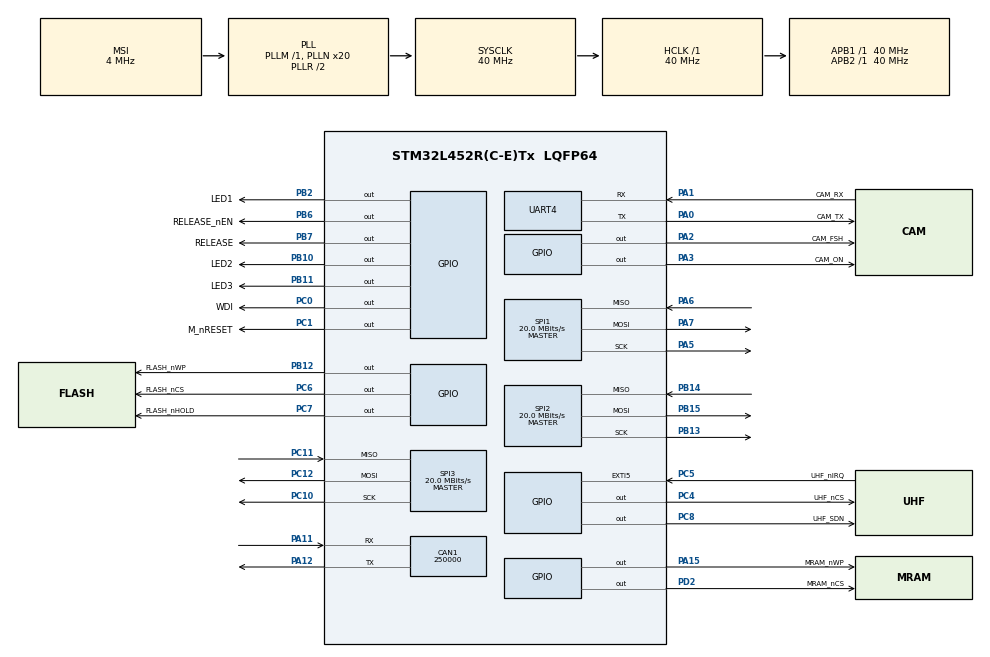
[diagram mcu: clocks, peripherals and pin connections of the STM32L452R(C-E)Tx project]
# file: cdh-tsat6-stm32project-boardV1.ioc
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CAN1.BS1=CAN_BS1_5TQ
CAN1.BS2=CAN_BS2_4TQ
CAN1.CalculateBaudRate=250000
CAN1.CalculateTimeBit=4000
CAN1.CalculateTimeQuantum=400.0
CAN1.Mode=CAN_MODE_LOOPBACK
Mcu.Family=STM32L4
Mcu.Name=STM32L452R(C-E)Tx
Mcu.Package=LQFP64
NVIC.CAN1_RX0_IRQn=true\:0\:0\:false\:false\:true\:true\:true\:true
NVIC.PriorityGroup=NVIC_PRIORITYGROUP_4
NVIC.TIM6_DAC_IRQn=true\:15\:0\:false\:false\:true\:false\:true\:true
NVIC.TimeBase=TIM6_DAC_IRQn
NVIC.TimeBaseIP=TIM6
PA0.GPIO_Label=CAM_TX
PA0.Mode=Asynchronous
PA0.Signal=UART4_TX
PA1.GPIO_Label=CAM_RX
PA1.Mode=Asynchronous
PA1.Signal=UART4_RX
PA11.Mode=CAN_Activate
PA11.Signal=CAN1_RX
PA12.Mode=CAN_Activate
PA12.Signal=CAN1_TX
PA13\ (JTMS/SWDIO).Mode=Trace_Asynchronous_SW
PA13\ (JTMS/SWDIO).Signal=SYS_JTMS-SWDIO
PA14\ (JTCK/SWCLK).Mode=Trace_Asynchronous_SW
PA14\ (JTCK/SWCLK).Signal=SYS_JTCK-SWCLK
PA15\ (JTDI).GPIO_Label=MRAM_nWP
PA15\ (JTDI).Signal=GPIO_Output
PA2.GPIO_Label=CAM_FSH
PA2.Signal=GPIO_Output
PA3.GPIO_Label=CAM_ON
PA3.Signal=GPIO_Output
PA5.Mode=Full_Duplex_Master
PA5.Signal=SPI1_SCK
PA6.Mode=Full_Duplex_Master
PA6.Signal=SPI1_MISO
PA7.Mode=Full_Duplex_Master
PA7.Signal=SPI1_MOSI
PB10.GPIO_Label=LED2
PB10.Signal=GPIO_Output
PB11.GPIO_Label=LED3
PB11.Signal=GPIO_Output
PB12.GPIO_Label=FLASH_nWP
PB12.Signal=GPIO_Output
PB13.Mode=Full_Duplex_Master
PB13.Signal=SPI2_SCK
PB14.Mode=Full_Duplex_Master
PB14.Signal=SPI2_MISO
PB15.Mode=Full_Duplex_Master
PB15.Signal=SPI2_MOSI
PB2.GPIO_Label=LED1
PB2.Signal=GPIO_Output
PB3\ (JTDO/TRACESWO).Mode=Trace_Asynchronous_SW
PB3\ (JTDO/TRACESWO).Signal=SYS_JTDO-SWO
PB6.GPIO_Label=RELEASE_nEN
PB6.Signal=GPIO_Output
PB7.GPIO_Label=RELEASE
PB7.Signal=GPIO_Output
PC0.GPIO_Label=WDI
PC0.Signal=GPIO_Output
PC1.GPIO_Label=M_nRESET
PC1.Signal=GPIO_Output
PC10.Mode=Full_Duplex_Master
PC10.Signal=SPI3_SCK
PC11.Mode=Full_Duplex_Master
PC11.Signal=SPI3_MISO
PC12.Mode=Full_Duplex_Master
PC12.Signal=SPI3_MOSI
PC4.GPIO_Label=UHF_nCS
PC4.Signal=GPIO_Output
PC5.GPIO_Label=UHF_nIRQ
PC5.Signal=GPXTI5
PC6.GPIO_Label=FLASH_nCS
PC6.Signal=GPIO_Output
PC7.GPIO_Label=FLASH_nHOLD
PC7.Signal=GPIO_Output
PC8.GPIO_Label=UHF_SDN
PC8.Signal=GPIO_Output
PD2.GPIO_Label=MRAM_nCS
PD2.Signal=GPIO_Output
ProjectManager.HeapSize=0x200
ProjectManager.StackSize=0x400
ProjectManager.TargetToolchain=STM32CubeIDE
RCC.ADCFreq_Value=16000000
RCC.AHBFreq_Value=40000000
RCC.APB1Freq_Value=40000000
RCC.APB1TimFreq_Value=40000000
RCC.APB2Freq_Value=40000000
RCC.APB2TimFreq_Value=40000000
RCC.CortexFreq_Value=40000000
RCC.HCLKFreq_Value=40000000
RCC.HSE_VALUE=8000000
RCC.HSI48_VALUE=48000000
RCC.HSI_VALUE=16000000
RCC.LSE_VALUE=32768
RCC.MSI_VALUE=4000000
RCC.PLLN=20
RCC.SYSCLKFreq_VALUE=40000000
RCC.SYSCLKSource=RCC_SYSCLKSOURCE_PLLCLK
RCC.USBFreq_Value=16000000
RCC.VCOOutputFreq_Value=80000000
SPI1.BaudRatePrescaler=SPI_BAUDRATEPRESCALER_2
SPI1.CalculateBaudRate=20.0 MBits/s
SPI1.DataSize=SPI_DATASIZE_8BIT
SPI1.Direction=SPI_DIRECTION_2LINES
SPI1.Mode=SPI_MODE_MASTER
SPI1.VirtualType=VM_MASTER
SPI2.BaudRatePrescaler=SPI_BAUDRATEPRESCALER_2
SPI2.CalculateBaudRate=20.0 MBits/s
SPI2.DataSize=SPI_DATASIZE_8BIT
SPI2.Direction=SPI_DIRECTION_2LINES
SPI2.Mode=SPI_MODE_MASTER
SPI2.VirtualType=VM_MASTER
SPI3.BaudRatePrescaler=SPI_BAUDRATEPRESCALER_2
SPI3.CalculateBaudRate=20.0 MBits/s
SPI3.DataSize=SPI_DATASIZE_8BIT
SPI3.Direction=SPI_DIRECTION_2LINES
SPI3.Mode=SPI_MODE_MASTER
SPI3.VirtualType=VM_MASTER
VP_RTC_VS_RTC_Activate.Mode=RTC_Enabled
VP_SYS_VS_tim6.Mode=TIM6
board=custom

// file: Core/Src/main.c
/* USER CODE BEGIN Header */
/**
  ******************************************************************************
  * @file           : main.c
  * @brief          : Main program body
  ******************************************************************************
  * @attention
  *
  * Copyright (c) 2022 STMicroelectronics.
  * All rights reserved.
  *
  * This software is licensed under terms that can be found in the LICENSE file
  * in the root directory of this software component.
  * If no LICENSE file comes with this software, it is provided AS-IS.
  *
  ******************************************************************************
  */
/* USER CODE END Header */
#include "main.h"

/* USER CODE BEGIN Includes */
#include "can.h"
/* USER CODE END Includes */

CAN_HandleTypeDef hcan1;

RTC_HandleTypeDef hrtc;

SPI_HandleTypeDef hspi1;
SPI_HandleTypeDef hspi2;
SPI_HandleTypeDef hspi3;

UART_HandleTypeDef huart4;

/* USER CODE BEGIN PV */
uint8_t               TxData[8];
/* USER CODE END PV */

void SystemClock_Config(void);
static void MX_GPIO_Init(void);
static void MX_CAN1_Init(void);
static void MX_SPI1_Init(void);
static void MX_SPI2_Init(void);
static void MX_SPI3_Init(void);
static void MX_UART4_Init(void);
static void MX_RTC_Init(void);

int main(void)
{

  /* MCU Configuration--------------------------------------------------------*/

  /* Reset of all peripherals, Initializes the Flash interface and the Systick. */
  HAL_Init();

  /* Configure the system clock */
  SystemClock_Config();

  /* Initialize all configured peripherals */
  MX_GPIO_Init();
  MX_CAN1_Init();
  MX_SPI1_Init();
  MX_SPI2_Init();
  MX_SPI3_Init();
  MX_UART4_Init();
  MX_RTC_Init();
  /* USER CODE BEGIN 2 */
  CANMessage_t static testMessage;
  	  	testMessage.DestinationID = 0x3;
  	  	testMessage.command = 0x1;
  	  	for(uint8_t index = 0; index <= 7; index++){
  	  		testMessage.data[index] = index;
  	  	}
  	  	testMessage.priority = 0x1;
  /* USER CODE END 2 */

  /* Infinite loop */
  while (1)
  {

    /* USER CODE BEGIN 3 */
	  HAL_GPIO_TogglePin(GPIOB, GPIO_PIN_11);
	  CAN_Transmit_Message(testMessage);
	  HAL_Delay(500);
  }
  /* USER CODE END 3 */
}

void SystemClock_Config(void)
{
  RCC_OscInitTypeDef RCC_OscInitStruct = {0};
  RCC_ClkInitTypeDef RCC_ClkInitStruct = {0};

  /** Configure the main internal regulator output voltage
  */
  if (HAL_PWREx_ControlVoltageScaling(PWR_REGULATOR_VOLTAGE_SCALE1) != HAL_OK)
  {
    Error_Handler();
  }

  /** Initializes the RCC Oscillators according to the specified parameters
  * in the RCC_OscInitTypeDef structure.
  */
  RCC_OscInitStruct.OscillatorType = RCC_OSCILLATORTYPE_LSI|RCC_OSCILLATORTYPE_MSI;
  RCC_OscInitStruct.LSIState = RCC_LSI_ON;
  RCC_OscInitStruct.MSIState = RCC_MSI_ON;
  RCC_OscInitStruct.MSICalibrationValue = 0;
  RCC_OscInitStruct.MSIClockRange = RCC_MSIRANGE_6;
  RCC_OscInitStruct.PLL.PLLState = RCC_PLL_ON;
  RCC_OscInitStruct.PLL.PLLSource = RCC_PLLSOURCE_MSI;
  RCC_OscInitStruct.PLL.PLLM = 1;
  RCC_OscInitStruct.PLL.PLLN = 20;
  RCC_OscInitStruct.PLL.PLLP = RCC_PLLP_DIV7;
  RCC_OscInitStruct.PLL.PLLQ = RCC_PLLQ_DIV2;
  RCC_OscInitStruct.PLL.PLLR = RCC_PLLR_DIV2;
  if (HAL_RCC_OscConfig(&RCC_OscInitStruct) != HAL_OK)
  {
    Error_Handler();
  }

  /** Initializes the CPU, AHB and APB buses clocks
  */
  RCC_ClkInitStruct.ClockType = RCC_CLOCKTYPE_HCLK|RCC_CLOCKTYPE_SYSCLK
                              |RCC_CLOCKTYPE_PCLK1|RCC_CLOCKTYPE_PCLK2;
  RCC_ClkInitStruct.SYSCLKSource = RCC_SYSCLKSOURCE_PLLCLK;
  RCC_ClkInitStruct.AHBCLKDivider = RCC_SYSCLK_DIV1;
  RCC_ClkInitStruct.APB1CLKDivider = RCC_HCLK_DIV1;
  RCC_ClkInitStruct.APB2CLKDivider = RCC_HCLK_DIV1;

  if (HAL_RCC_ClockConfig(&RCC_ClkInitStruct, FLASH_LATENCY_2) != HAL_OK)
  {
    Error_Handler();
  }
}

static void MX_CAN1_Init(void)
{

  hcan1.Instance = CAN1;
  hcan1.Init.Prescaler = 16;
  hcan1.Init.Mode = CAN_MODE_LOOPBACK;
  hcan1.Init.SyncJumpWidth = CAN_SJW_1TQ;
  hcan1.Init.TimeSeg1 = CAN_BS1_5TQ;
  hcan1.Init.TimeSeg2 = CAN_BS2_4TQ;
  hcan1.Init.TimeTriggeredMode = DISABLE;
  hcan1.Init.AutoBusOff = DISABLE;
  hcan1.Init.AutoWakeUp = DISABLE;
  hcan1.Init.AutoRetransmission = DISABLE;
  hcan1.Init.ReceiveFifoLocked = DISABLE;
  hcan1.Init.TransmitFifoPriority = DISABLE;
  if (HAL_CAN_Init(&hcan1) != HAL_OK)
  {
    Error_Handler();
  }
  /* USER CODE BEGIN CAN1_Init 2 */
  CAN_Boot();
  /* USER CODE END CAN1_Init 2 */

}

static void MX_RTC_Init(void)
{

  /** Initialize RTC Only
  */
  hrtc.Instance = RTC;
  hrtc.Init.HourFormat = RTC_HOURFORMAT_24;
  hrtc.Init.AsynchPrediv = 127;
  hrtc.Init.SynchPrediv = 255;
  hrtc.Init.OutPut = RTC_OUTPUT_DISABLE;
  hrtc.Init.OutPutRemap = RTC_OUTPUT_REMAP_NONE;
  hrtc.Init.OutPutPolarity = RTC_OUTPUT_POLARITY_HIGH;
  hrtc.Init.OutPutType = RTC_OUTPUT_TYPE_OPENDRAIN;
  if (HAL_RTC_Init(&hrtc) != HAL_OK)
  {
    Error_Handler();
  }

}

static void MX_SPI1_Init(void)
{

  /* SPI1 parameter configuration*/
  hspi1.Instance = SPI1;
  hspi1.Init.Mode = SPI_MODE_MASTER;
  hspi1.Init.Direction = SPI_DIRECTION_2LINES;
  hspi1.Init.DataSize = SPI_DATASIZE_8BIT;
  hspi1.Init.CLKPolarity = SPI_POLARITY_LOW;
  hspi1.Init.CLKPhase = SPI_PHASE_1EDGE;
  hspi1.Init.NSS = SPI_NSS_SOFT;
  hspi1.Init.BaudRatePrescaler = SPI_BAUDRATEPRESCALER_2;
  hspi1.Init.FirstBit = SPI_FIRSTBIT_MSB;
  hspi1.Init.TIMode = SPI_TIMODE_DISABLE;
  hspi1.Init.CRCCalculation = SPI_CRCCALCULATION_DISABLE;
  hspi1.Init.CRCPolynomial = 7;
  hspi1.Init.CRCLength = SPI_CRC_LENGTH_DATASIZE;
  hspi1.Init.NSSPMode = SPI_NSS_PULSE_ENABLE;
  if (HAL_SPI_Init(&hspi1) != HAL_OK)
  {
    Error_Handler();
  }

}

static void MX_SPI2_Init(void)
{

  /* SPI2 parameter configuration*/
  hspi2.Instance = SPI2;
  hspi2.Init.Mode = SPI_MODE_MASTER;
  hspi2.Init.Direction = SPI_DIRECTION_2LINES;
  hspi2.Init.DataSize = SPI_DATASIZE_8BIT;
  hspi2.Init.CLKPolarity = SPI_POLARITY_LOW;
  hspi2.Init.CLKPhase = SPI_PHASE_1EDGE;
  hspi2.Init.NSS = SPI_NSS_SOFT;
  hspi2.Init.BaudRatePrescaler = SPI_BAUDRATEPRESCALER_2;
  hspi2.Init.FirstBit = SPI_FIRSTBIT_MSB;
  hspi2.Init.TIMode = SPI_TIMODE_DISABLE;
  hspi2.Init.CRCCalculation = SPI_CRCCALCULATION_DISABLE;
  hspi2.Init.CRCPolynomial = 7;
  hspi2.Init.CRCLength = SPI_CRC_LENGTH_DATASIZE;
  hspi2.Init.NSSPMode = SPI_NSS_PULSE_ENABLE;
  if (HAL_SPI_Init(&hspi2) != HAL_OK)
  {
    Error_Handler();
  }

}

static void MX_SPI3_Init(void)
{

  /* SPI3 parameter configuration*/
  hspi3.Instance = SPI3;
  hspi3.Init.Mode = SPI_MODE_MASTER;
  hspi3.Init.Direction = SPI_DIRECTION_2LINES;
  hspi3.Init.DataSize = SPI_DATASIZE_8BIT;
  hspi3.Init.CLKPolarity = SPI_POLARITY_LOW;
  hspi3.Init.CLKPhase = SPI_PHASE_1EDGE;
  hspi3.Init.NSS = SPI_NSS_SOFT;
  hspi3.Init.BaudRatePrescaler = SPI_BAUDRATEPRESCALER_2;
  hspi3.Init.FirstBit = SPI_FIRSTBIT_MSB;
  hspi3.Init.TIMode = SPI_TIMODE_DISABLE;
  hspi3.Init.CRCCalculation = SPI_CRCCALCULATION_DISABLE;
  hspi3.Init.CRCPolynomial = 7;
  hspi3.Init.CRCLength = SPI_CRC_LENGTH_DATASIZE;
  hspi3.Init.NSSPMode = SPI_NSS_PULSE_ENABLE;
  if (HAL_SPI_Init(&hspi3) != HAL_OK)
  {
    Error_Handler();
  }

}

static void MX_UART4_Init(void)
{

  huart4.Instance = UART4;
  huart4.Init.BaudRate = 115200;
  huart4.Init.WordLength = UART_WORDLENGTH_8B;
  huart4.Init.StopBits = UART_STOPBITS_1;
  huart4.Init.Parity = UART_PARITY_NONE;
  huart4.Init.Mode = UART_MODE_TX_RX;
  huart4.Init.HwFlowCtl = UART_HWCONTROL_NONE;
  huart4.Init.OverSampling = UART_OVERSAMPLING_16;
  huart4.Init.OneBitSampling = UART_ONE_BIT_SAMPLE_DISABLE;
  huart4.AdvancedInit.AdvFeatureInit = UART_ADVFEATURE_NO_INIT;
  if (HAL_UART_Init(&huart4) != HAL_OK)
  {
    Error_Handler();
  }

}

static void MX_GPIO_Init(void)
{
  GPIO_InitTypeDef GPIO_InitStruct = {0};

  /* GPIO Ports Clock Enable */
  __HAL_RCC_GPIOC_CLK_ENABLE();
  __HAL_RCC_GPIOA_CLK_ENABLE();
  __HAL_RCC_GPIOB_CLK_ENABLE();
  __HAL_RCC_GPIOD_CLK_ENABLE();

  /*Configure GPIO pin Output Level */
  HAL_GPIO_WritePin(GPIOC, WDI_Pin|M_nRESET_Pin|UHF_nCS_Pin|FLASH_nCS_Pin
                          |FLASH_nHOLD_Pin|UHF_SDN_Pin, GPIO_PIN_RESET);

  /*Configure GPIO pin Output Level */
  HAL_GPIO_WritePin(GPIOA, CAM_FSH_Pin|CAM_ON_Pin|MRAM_nWP_Pin, GPIO_PIN_RESET);

  /*Configure GPIO pin Output Level */
  HAL_GPIO_WritePin(GPIOB, LED1_Pin|LED2_Pin|LED3_Pin|FLASH_nWP_Pin
                          |RELEASE_nEN_Pin|RELEASE_Pin, GPIO_PIN_RESET);

  /*Configure GPIO pin Output Level */
  HAL_GPIO_WritePin(MRAM_nCS_GPIO_Port, MRAM_nCS_Pin, GPIO_PIN_RESET);

  /*Configure GPIO pins : WDI_Pin M_nRESET_Pin UHF_nCS_Pin FLASH_nCS_Pin
                           FLASH_nHOLD_Pin UHF_SDN_Pin */
  GPIO_InitStruct.Pin = WDI_Pin|M_nRESET_Pin|UHF_nCS_Pin|FLASH_nCS_Pin
                          |FLASH_nHOLD_Pin|UHF_SDN_Pin;
  GPIO_InitStruct.Mode = GPIO_MODE_OUTPUT_PP;
  GPIO_InitStruct.Pull = GPIO_NOPULL;
  GPIO_InitStruct.Speed = GPIO_SPEED_FREQ_LOW;
  HAL_GPIO_Init(GPIOC, &GPIO_InitStruct);

  /*Configure GPIO pins : CAM_FSH_Pin CAM_ON_Pin MRAM_nWP_Pin */
  GPIO_InitStruct.Pin = CAM_FSH_Pin|CAM_ON_Pin|MRAM_nWP_Pin;
  GPIO_InitStruct.Mode = GPIO_MODE_OUTPUT_PP;
  GPIO_InitStruct.Pull = GPIO_NOPULL;
  GPIO_InitStruct.Speed = GPIO_SPEED_FREQ_LOW;
  HAL_GPIO_Init(GPIOA, &GPIO_InitStruct);

  /*Configure GPIO pin : UHF_nIRQ_Pin */
  GPIO_InitStruct.Pin = UHF_nIRQ_Pin;
  GPIO_InitStruct.Mode = GPIO_MODE_IT_RISING;
  GPIO_InitStruct.Pull = GPIO_NOPULL;
  HAL_GPIO_Init(UHF_nIRQ_GPIO_Port, &GPIO_InitStruct);

  /*Configure GPIO pins : LED1_Pin LED2_Pin LED3_Pin FLASH_nWP_Pin
                           RELEASE_nEN_Pin RELEASE_Pin */
  GPIO_InitStruct.Pin = LED1_Pin|LED2_Pin|LED3_Pin|FLASH_nWP_Pin
                          |RELEASE_nEN_Pin|RELEASE_Pin;
  GPIO_InitStruct.Mode = GPIO_MODE_OUTPUT_PP;
  GPIO_InitStruct.Pull = GPIO_NOPULL;
  GPIO_InitStruct.Speed = GPIO_SPEED_FREQ_LOW;
  HAL_GPIO_Init(GPIOB, &GPIO_InitStruct);

  /*Configure GPIO pin : MRAM_nCS_Pin */
  GPIO_InitStruct.Pin = MRAM_nCS_Pin;
  GPIO_InitStruct.Mode = GPIO_MODE_OUTPUT_PP;
  GPIO_InitStruct.Pull = GPIO_NOPULL;
  GPIO_InitStruct.Speed = GPIO_SPEED_FREQ_LOW;
  HAL_GPIO_Init(MRAM_nCS_GPIO_Port, &GPIO_InitStruct);

}

/* USER CODE BEGIN 4 */
/**
  * @brief  Rx Fifo 0 message pending callback
  * @param  hcan: pointer to a CAN_HandleTypeDef structure that contains
  *         the configuration information for the specified CAN.
  * @retval None
  */
void HAL_CAN_RxFifo0MsgPendingCallback(CAN_HandleTypeDef *hcan)
{
	CAN_Message_Received();
}
/* USER CODE END 4 */

void HAL_TIM_PeriodElapsedCallback(TIM_HandleTypeDef *htim)
{
  if (htim->Instance == TIM6) {
    HAL_IncTick();
  }
}

void Error_Handler(void)
{
  __disable_irq();
  while (1)
  {
  }
}
